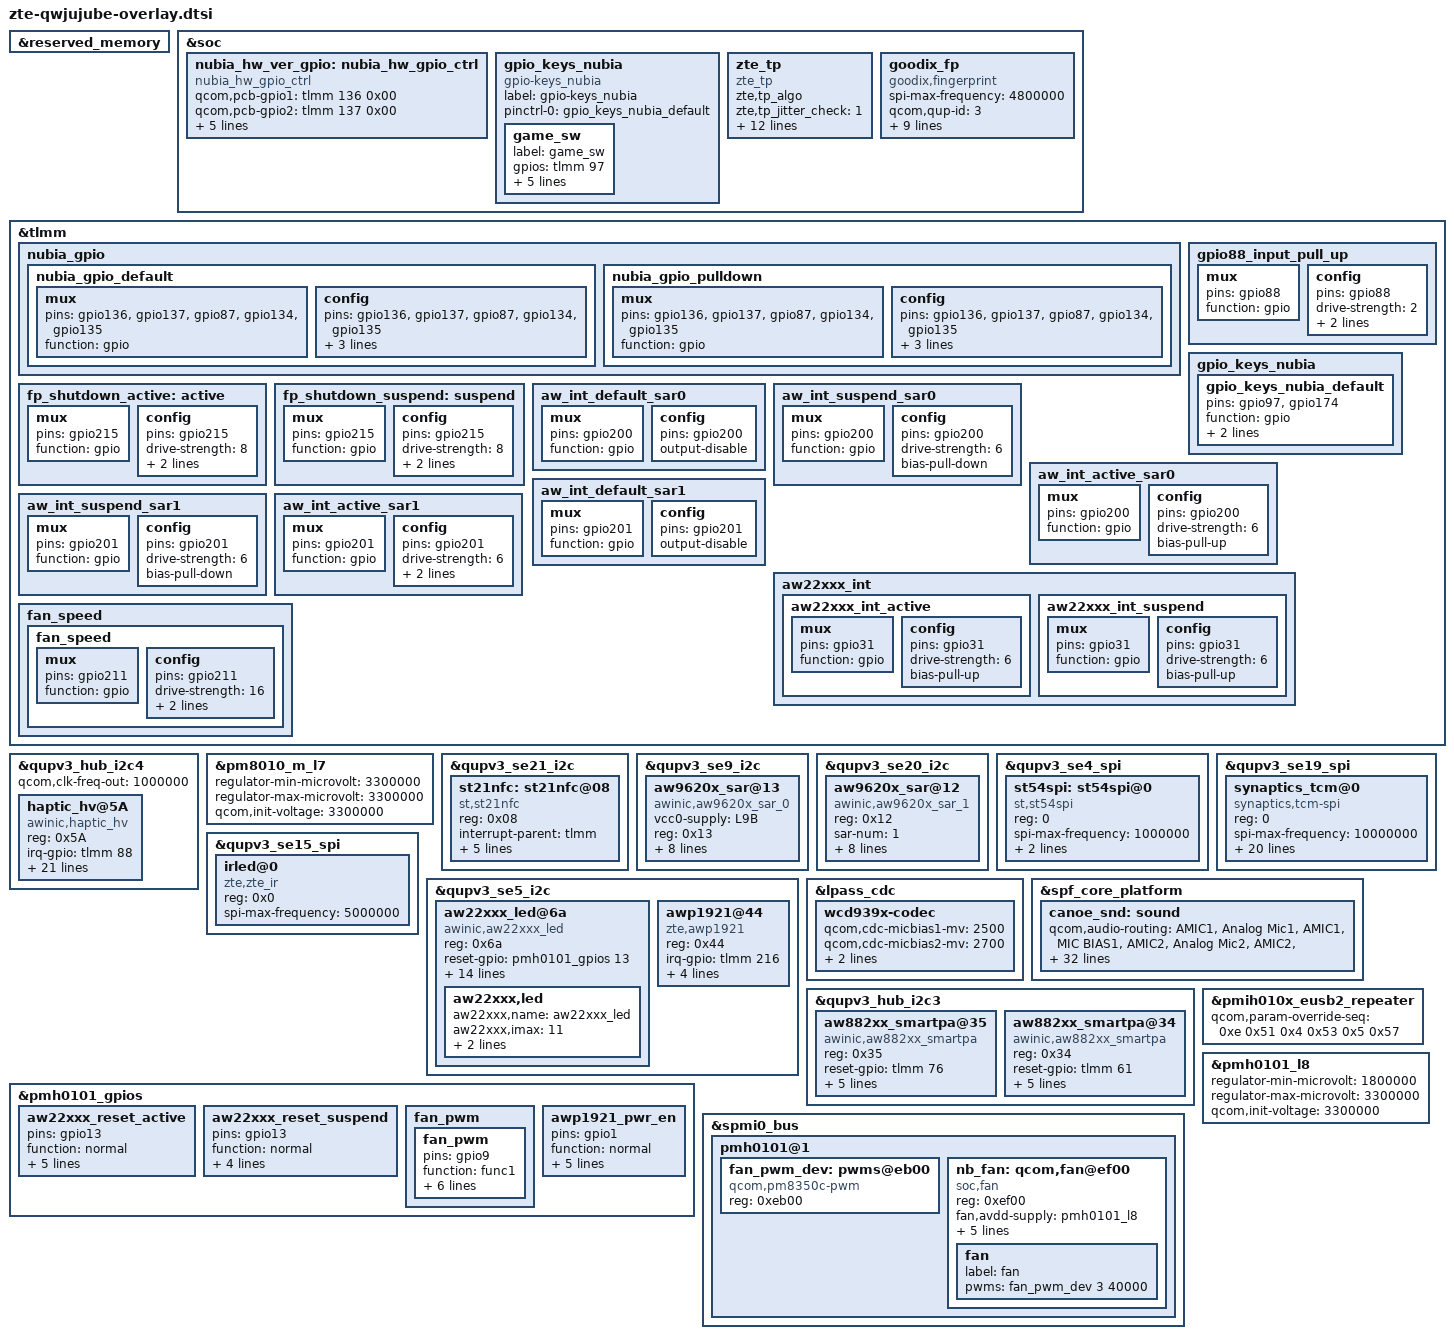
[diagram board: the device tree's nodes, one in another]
/* dtsi for aston board (NX809J)*/
#include <dt-bindings/gpio/gpio.h>

&reserved_memory {
};

&soc {
    nubia_hw_ver_gpio: nubia_hw_gpio_ctrl {
        compatible = "nubia_hw_gpio_ctrl";
        qcom,pcb-gpio1 = <&tlmm 136 0x00>;
        qcom,pcb-gpio2 = <&tlmm 137 0x00>;
        qcom,pcb-gpio3 = <&tlmm 87 0x00>;
        qcom,rf-gpio1 = <&tlmm 134 0x00>;
        qcom,rf-gpio2 = <&tlmm 135 0x00>;
        pinctrl-names = "pull_up_default","pull_down_default";
        pinctrl-0 = <&nubia_gpio_default>;
        pinctrl-1 = <&nubia_gpio_pulldown>;
    };

	gpio_keys_nubia {
		status = "ok";
		compatible = "gpio-keys_nubia";
		label = "gpio-keys_nubia";
		pinctrl-names ="default";
		pinctrl-0 = <&gpio_keys_nubia_default>;
		game_sw {
			label = "game_sw";
			/* In down state ↓, S=1/N=0, gpio97 is high, gpio174 is low; */
			/* In up state ↑, S=0/N=1, gpio97 is low, gpio174 is high; */
			gpios = <&tlmm 97 0>;
			gpion = <&tlmm 174 0>;
			linux,input-type = <5>;
			linux,code = <0x0f>;
			debounce-interval = <30>;
			gpio-key,wakeup;
		};
	};

	zte_tp:zte_tp {
		compatible = "zte_tp";
		zte,tp_algo;
		zte,tp_jitter_check = <1>;
		zte,tp_jitter_timer = <80>;
		zte,tp_long_press;
		zte,tp_long_press_timer = <800>;
		zte,tp_long_press_left_v = <20>;
		zte,tp_long_press_right_v = <20>;
		zte,tp_long_press_left_h = <20>; /*camera */
		zte,tp_long_press_right_h = <20>; /*charger */
		zte,tp_edge_click_suppression_pixel = <20>;
		zte,ufp_enable;
		zte,ufp_circle_center_x = <6080>;
		zte,ufp_circle_center_y = <20240>;
		zte,ufp_circle_radius = <1200>;
	};
};

&tlmm{
    nubia_gpio {
        nubia_gpio_default: nubia_gpio_default {
            mux {
                pins = "gpio136", "gpio137", "gpio87", "gpio134", "gpio135";
                function = "gpio";
            };
            config {
                pins = "gpio136", "gpio137", "gpio87", "gpio134", "gpio135";
                driver-strength = <2>; /* 2mA */
                bias-pull-up;
                input-enable;
            };
        };
        nubia_gpio_pulldown: nubia_gpio_pulldown {
            mux {
                pins = "gpio136", "gpio137", "gpio87", "gpio134", "gpio135";
                function = "gpio";
            };
            config {
                pins = "gpio136", "gpio137", "gpio87", "gpio134", "gpio135";
                driver-strength = <2>; /* 2mA */
                bias-pull-down;
                input-enable;
            };
        };
    };

    gpio88_input_pull_up: gpio88_input_pull_up {
            mux {
                pins = "gpio88";
                function = "gpio";
            };

            config {
                pins = "gpio88";
                drive-strength = <2>;
                bias-pull-up;
                input-enable;
            };
    };

	gpio_keys_nubia {
		gpio_keys_nubia_default: gpio_keys_nubia_default {
			pins = "gpio97", "gpio174";
			function = "gpio";
			input-enable;
			bias-disable;
		};
	};
};

/* add zte haptic  */
&qupv3_hub_i2c4  {
	status = "ok";
	qcom,clk-freq-out = <1000000>;
	haptic_hv@5A {
		compatible = "awinic,haptic_hv";
		reg = <0x5A>;
		irq-gpio = <&tlmm 88 0>;
		reset-gpio = <&tlmm 94 0>;
		pinctrl-names = "irq_active";
		pinctrl-0 = <&gpio88_input_pull_up>;
		f0_pre = < 1700 >;
		mode = /bits/ 8 < 5 >;

		aw8693x_f0_cali_percent = /bits/ 8 < 15 >;
		aw8693x_gain_bypass = /bits/ 8 < 1 >;
		aw8693x_uvlo_vol_default = /bits/ 8 < 0 >;
		aw8693x_cont_smart_loop = /bits/ 8 < 0 >;
		aw8693x_cont_drv1_lvl = /bits/ 8 < 0x7F >;
		aw8693x_cont_lra_vrms = < 1000 >;
		aw8693x_cont_drv1_time = /bits/ 8 < 0x04 >;
		aw8693x_cont_drv2_time = /bits/ 8 < 0x14 >;
		aw8693x_cont_track_margin = /bits/ 8 < 0x0F >;
		aw8693x_cont_brk_gain = /bits/ 8 < 0x08 >;
		aw8693x_cont_brk_time = /bits/ 8 < 0x08 >;
		aw8693x_duration_time = /bits/ 8 < 20 30 60 >;
		aw8693x_d2s_gain = /bits/ 8 < 0x04 >;
		aw8693x_trig_config = /bits/ 8 < 0 0 0 1 0 2 0 0
						 0 0 0 1 0 2 0 0
						 0 0 0 1 0 2 0 0 >;
		aw8693x_bst_vol_default = /bits/ 8 < 0x0f >;
		aw8693x_is_enabled_track_en;
		/* aw8693x_is_enabled_auto_bst; */
		/* aw8693x_is_enabled_one_wire; */
	};
};

&soc {
	goodix_fp {
		status = "ok";
		compatible = "goodix,fingerprint";
		spi-max-frequency = <4800000>;
		qcom,qup-id = <3>;
		reg = <0>;

		interrupt-parent = <&tlmm>;
		interrupts = <99 0x2008>;
		pinctrl-names = "goodix_active", "goodix_suspend";
		pinctrl-0 = <&fp_shutdown_active>;
		pinctrl-1 = <&fp_shutdown_suspend>;

		fp-gpio-reset = <&tlmm 215 0x0>;
		fp-gpio-irq = <&tlmm 99 0x2008>;
		vdd-supply = <&L7M>;
		interrupt-names = "goodix_wake_up";

		panel = <&dsi_bf375_rm692h5_6p8_magic_dsc_cmd>;
	};
};

&pm8010_m_l7 {
        regulator-min-microvolt = <3300000>;
        regulator-max-microvolt = <3300000>;
        qcom,init-voltage = <3300000>;
};

&tlmm {
    fp_shutdown_active:active{
        mux{
            pins = "gpio215";
            function = "gpio";
        };
        config{
            pins = "gpio215";
            drive-strength = <8>;
            bias-disable;
            output-high;
        };
    };

    fp_shutdown_suspend:suspend{
        mux{
            pins = "gpio215";
            function = "gpio";
        };
        config{
            pins = "gpio215";
            drive-strength = <8>;
            bias-disable;
            output-low;
        };
    };

	aw_int_default_sar0: aw_int_default_sar0 {
			mux {
				pins = "gpio200";
				function = "gpio";
			};
			config {
				pins = "gpio200";
				output-disable;
			};
		};
	aw_int_suspend_sar0: aw_int_suspend_sar0 {
		mux {
				pins = "gpio200";
				function = "gpio";
			};
		config {
				pins = "gpio200";
				drive-strength = <6>;
				bias-pull-down;
		   };
		};
	aw_int_active_sar0: aw_int_active_sar0 {
		mux {
				pins = "gpio200";
				function = "gpio";
			};
		config {
				pins = "gpio200";
				drive-strength = <6>;
				bias-pull-up;
			};
		};
	aw_int_default_sar1: aw_int_default_sar1 {
		mux {
				pins = "gpio201";
				function = "gpio";
		};
		config{
				pins = "gpio201";
				output-disable;
		};
	};
	aw_int_suspend_sar1: aw_int_suspend_sar1 {
		mux {
				pins = "gpio201";
				function = "gpio";
	};
		config{
				pins = "gpio201";
				drive-strength = <6>;
				bias-pull-down;
		};
	};
	aw_int_active_sar1: aw_int_active_sar1 {
		mux {
				pins = "gpio201";
				function = "gpio";
		};
		config {
				pins = "gpio201";
				drive-strength = <6>;
				bias-pull-up;
				qcom,i2c_pull = <0>;
		};
	};

};

&qupv3_se21_i2c {
    status = "ok";
    /delete-node/ nq@28;
    st21nfc: st21nfc@08 {
        compatible = "st,st21nfc";
        reg = <0x08>;
        interrupt-parent = <&tlmm>;
        interrupts = <75  0>;
        reset-gpios = <&tlmm 34 0x00>;
        irq-gpios = <&tlmm 75 0x00>;
        //boost-gpios = <&tlmm 90 0x00>;
        //pidle-gpios = <&tlmm 48 0x00>;
        clkreq-gpios = <&tlmm 35 0x00>;
        //clocks = <&clock_rpmh RPMH_RF_CLK3>;
        //clock-names = "nfc_ref_clk";
        st,clk_pinctrl;
        status = "ok";
    };
};

&qupv3_se9_i2c {
		status = "ok";
		aw9620x_sar@13 {
			compatible = "awinic,aw9620x_sar_0";
			vcc0-supply = <&L9B>;
			reg = <0x13>;
			sar-num = < 0 >;
			interrupt-parent = < &tlmm >;
			interrupts = <200 0>;
			irq-gpio = <&tlmm 200 0>;
			pinctrl-names = "aw_int_default_sar0", "aw_int_active_sar0", "aw_int_suspend_sar0";
			pinctrl-0 = <&aw_int_default_sar0>;
			pinctrl-1 = <&aw_int_active_sar0>;
			pinctrl-2 = <&aw_int_suspend_sar0>;
			channel_use_flag = <0x01>;
			status = "okay";
		};
};

&qupv3_se20_i2c {
		status = "ok";
		aw9620x_sar@12 {
			compatible = "awinic,aw9620x_sar_1";
			reg = < 0x12 >;
			sar-num = < 1 >;
			interrupt-parent = < &tlmm >;
			interrupts = <201 0>;
			irq-gpio = <&tlmm 201 0>;
			pinctrl-names = "aw_int_default_sar1", "aw_int_active_sar1", "aw_int_suspend_sar1";
			pinctrl-0 = <&aw_int_default_sar1>;
			pinctrl-1 = <&aw_int_active_sar1>;
			pinctrl-2 = <&aw_int_suspend_sar1>;
			vcc1-supply = <&L9B>;
			channel_use_flag = <0x01>;
			status = "okay";
		};
};

&qupv3_se4_spi {
    status = "ok";
    st54spi: st54spi@0 {
        compatible = "st,st54spi";
        reg = <0>;
        spi-max-frequency = <1000000>;
        /* gpio used as SE_PWR_REQ or SE_nRESET */
        gpio-power_nreset-std = <&tlmm 46 0x00>;

        /* Power management mode: none, ST54H (default), ST54J */
        power_mode = "ST54J";
        status = "ok";
    };
};

&qupv3_se19_spi {

	status = "ok";

	synaptics_tcm@0 {
		compatible = "synaptics,tcm-spi";
		reg = <0>;
		spi-max-frequency = <10000000>;
		interrupt-parent = <&tlmm>;
		interrupts = <158 0x2008>;
		synaptics,vdd-name = "vdd";
		synaptics,avdd-name = "avdd";
		vdd-supply = <&L4B>;
		avdd-supply = <&L14B>;
		synaptics,power-delay-ms = <200>;
		synaptics,irq-gpio = <&tlmm 158 0x2008>;
		synaptics,irq-on-state = <0>;
		synaptics,reset-gpio = <&tlmm 66 0x0000>;
		synaptics,reset-on-state = <0>;
		synaptics,reset-active-ms = <20>;
		synaptics,reset-delay-ms = <200>;
		synaptics,spi-mode = <0>;
		synaptics,spi-byte-delay-us = <0>;
		synaptics,spi-block-delay-us = <0>;

		pinctrl-names = "ts_active", "ts_suspend";
		pinctrl-0 = <&ts_active>;
		pinctrl-1 = <&ts_int_suspend &ts_reset_suspend>;
		pinctrl-2 = <&ts_release>;

		panel = <&dsi_bf375_rm692h5_6p8_magic_dsc_cmd>;
	};
};

&qupv3_se15_spi {
    status = "ok";
    irled@0 {
        status = "ok";
        compatible = "zte,zte_ir";
        reg = <0x0>;
        spi-max-frequency = <5000000>;
    };
};

&qupv3_se5_i2c {
        status = "okay";
	/*aw22xxx_led*/
	aw22xxx_led@6a {
	status = "okay";
		compatible = "awinic,aw22xxx_led";
		reg = <0x6a>;
		reset-gpio = <&pmh0101_gpios 13 0x0>;
		nubia_ver-gpio = <&tlmm 7 1>;
		interrupt-parent = <&tlmm>;
		interrupts = <31 0x2002>;
		irq-gpio = <&tlmm 31 0x2002>;
		qcom,clk-freq-out = <400000>;
		pinctrl-names = "aw22xxx_led_default", "aw22xxx_led_sleep";
		pinctrl-0 = <&aw22xxx_int_active &aw22xxx_reset_active>;
		pinctrl-1 = <&aw22xxx_int_suspend &aw22xxx_reset_suspend>;
		cfg_custom_en = <1>;
		/*aw22xxx_cfg_name[0:13] en flag */
		cfg_base_en = <1 1 1 1 0 0 0 0 1 1 1 1 1 1 1>;
		/*steady lighting up,breath,flashing,flow,ripple,echo,hopping,fast flashing,follows the audio,two flashing*/
		cfg_modex_count = <14 14 14 7 7 7 7 14 15 7>;
		touch_modex_count = <14 14 14 7 7 7 7 14 15 7>;
		fan_modex_count = <16 16 16 16 16>;
		aw22xxx,led {
			aw22xxx,name = "aw22xxx_led";
			aw22xxx,imax = <11>;
			aw22xxx,brightness = <128>;
			aw22xxx,max_brightness = <255>;
		};
	};

	awp1921@44 {
		compatible = "zte,awp1921","awinic,aw86320";
		reg = < 0x44 >;
		irq-gpio = <&tlmm 216 0x00>;
		power-en = <&pmh0101_gpios 1 0>;
		//is_fifo_method_play;
		is_reg_method_play;
		atsin0_polor = < 0x00 >;
		atsin0_phase = < 0x00 >;
		status = "okay";
	};
};

/*aw22xxx_led*/
&pmh0101_gpios {
    aw22xxx_reset_active: aw22xxx_reset_active {
        pins = "gpio13";
        function = "normal";
        qcom,drive-strength = <2>;
        input-disable;
        output-enable;
        output-high;
        power-source = <0>;
    };

    aw22xxx_reset_suspend: aw22xxx_reset_suspend {
        pins = "gpio13";
        function = "normal";
        qcom,drive-strength = <2>;
        input-disable;
        output-enable;
        output-low;
    };
};

&tlmm{
	aw22xxx_int {
		aw22xxx_int_active: aw22xxx_int_active {
			mux {
				pins = "gpio31";
				function = "gpio";
			};
			config {
				pins = "gpio31";
				drive-strength = <6>;
				bias-pull-up;
			};
		};
		aw22xxx_int_suspend: aw22xxx_int_suspend {
			mux {
				pins = "gpio31";
				function = "gpio";
			};
			config {
				pins = "gpio31";
				drive-strength = <6>;
				bias-pull-up;
			};
		};
	};
};

&lpass_cdc {
	wcd939x-codec {
		/* zte modify for redmagic headset no capture issue. */
		qcom,cdc-micbias1-mv = <2500>;
		qcom,cdc-micbias2-mv = <2700>;
		qcom,cdc-micbias3-mv = <2500>;
		qcom,cdc-micbias4-mv = <2500>;
	};
};

&spf_core_platform {
	canoe_snd: sound {
		qcom,audio-routing =
			"AMIC1", "Analog Mic1",
			"AMIC1", "MIC BIAS1",
			"AMIC2", "Analog Mic2",
			"AMIC2", "MIC BIAS2",
			"AMIC3", "Analog Mic3",
			"AMIC3", "MIC BIAS3",
			"AMIC4", "Analog Mic4",
			"AMIC4", "MIC BIAS4",
			"AMIC5", "Analog Mic5",
			"AMIC5", "MIC BIAS4",
			"VA AMIC1", "Analog Mic1",
			"VA AMIC1", "VA MIC BIAS1",
			"VA AMIC2", "Analog Mic2",
			"VA AMIC2", "VA MIC BIAS2",
			"VA AMIC3", "Analog Mic3",
			"VA AMIC3", "VA MIC BIAS3",
			"VA AMIC4", "Analog Mic4",
			"VA AMIC4", "VA MIC BIAS3",
			"VA AMIC5", "Analog Mic5",
			"VA AMIC5", "VA MIC BIAS4",
			"TX DMIC0", "Digital Mic0",
			"TX DMIC0", "MIC BIAS1",
			"TX DMIC1", "Digital Mic1",
			"TX DMIC1", "MIC BIAS1",
			"TX DMIC2", "Digital Mic2",
			"TX DMIC2", "MIC BIAS3",
			"TX DMIC3", "Digital Mic3",
			"TX DMIC3", "MIC BIAS3",
			"IN1_HPHL", "HPHL_OUT",
			"IN2_HPHR", "HPHR_OUT",
			"IN3_EAR", "AUX_OUT",
			"RX_TX DEC0_INP", "TX DEC0 MUX",
			"RX_TX DEC1_INP", "TX DEC1 MUX",
			"RX_TX DEC2_INP", "TX DEC2 MUX",
			"RX_TX DEC3_INP", "TX DEC3 MUX",
			"TX SWR_INPUT", "WCD_TX_OUTPUT",
			"VA SWR_INPUT", "VA_SWR_CLK",
			"VA SWR_INPUT", "WCD_TX_OUTPUT",
			"VA_AIF1 CAP", "VA_SWR_CLK",
			"VA_AIF2 CAP", "VA_SWR_CLK",
			"VA_AIF3 CAP", "VA_SWR_CLK",
			"VA DMIC0", "Digital Mic0",
			"VA DMIC1", "Digital Mic1",
			"VA DMIC2", "Digital Mic2",
			"VA DMIC3", "Digital Mic3",
			"VA DMIC0", "VA MIC BIAS1",
			"VA DMIC1", "VA MIC BIAS1",
			"VA DMIC2", "VA MIC BIAS3",
			"VA DMIC3", "VA MIC BIAS3";
		qcom,msm-mbhc-usbc-audio-supported = <0>;
		qcom,msm-mbhc-hphl-swh = <1>;
		qcom,msm-mbhc-gnd-swh = <1>;
		qcom,msm-mbhc-hs-mic-max-threshold-mv = <2700>;
	};
};

/* AWINIC AW882XX Smart PA */
&qupv3_hub_i2c3 {
	status = "okay";
	aw882xx_smartpa@35 {
		compatible = "awinic,aw882xx_smartpa";
		reg = <0x35>;
		reset-gpio = <&tlmm 76 0>;
		sync-load = <1>;
		sound-channel = <0>;
		aw-re-min = <4000>;
		aw-re-max= <30000>;
		aw-cali-mode = "none";
	};
	aw882xx_smartpa@34 {
		compatible = "awinic,aw882xx_smartpa";
		reg = <0x34>;
		reset-gpio = <&tlmm 61 0>;
		/* irq-gpio = <&tlmm xx 0x2008> */
		sync-load = <1>;
		sound-channel = <1>; /* 0: pri_l, 1:pri_r, 2:sec_l, 3:sec_r */
		aw-re-min = <4000>;
		aw-re-max= <30000>;
		aw-cali-mode = "none";
	};
};
/* AWINIC AW882XX Smart PA End */

/*fan start*/
&tlmm {
    fan_speed{
        fan_speed: fan_speed {
			mux {
				pins = "gpio211";
				function = "gpio";
			};
			config {
				pins = "gpio211";
				drive-strength = <16>;
				bias-pull-up;
				input-enable;
			};

        };
    };
};

&pmh0101_gpios {
    fan_pwm {
        fan_pwm: fan_pwm {
			pins = "gpio9";
			function = "func1";
			input-disable;
			output-enable;
			output-high;
			qcom,drive-strength = <3>;
			power-source = <0>;     /* 1.8V */
			drive-push-pull;
	    };
    };

    awp1921_pwr_en: awp1921_pwr_en {
        pins = "gpio1";
        function = "normal";
        qcom,drive-strength = <2>;
        input-disable;
        output-enable;
        output-high;
        power-source = <0>;      /* 1.8V */
    };

};

&pmih010x_eusb2_repeater {
	qcom,param-override-seq =
		/* <value reg_offset> */
		/* Adjust HS trasmit amplitude */
		<0xe 0x51
		/* HS Disconnect Threshold */
		 0x4 0x53
		/* Tx pre-emphasis tuning */
		 0x5 0x57>;
};

&pmh0101_l8 {
        regulator-min-microvolt = <1800000>;
        regulator-max-microvolt = <3300000>;
        qcom,init-voltage = <3300000>;
};


&spmi0_bus {
    pmh0101@1 {
        fan_pwm_dev: pwms@eb00 {
            compatible = "qcom,pm8350c-pwm";
            reg = <0xeb00>;
            #address-cells = <1>;
            #size-cells = <0>;
            #pwm-cells = <2>;
        };

        nb_fan: qcom,fan@ef00 {
            compatible = "soc,fan";
            reg = <0xef00>;
            fan,avdd-supply = <&pmh0101_l8>;
            regulator-names = "avdd";
            pinctrl-names ="default";
            pinctrl-0 =<&fan_speed &fan_pwm>;
            fan,pwm-gpio = <&pmh0101_gpios 9 GPIO_ACTIVE_HIGH>;
            fan,speed-gpio = <&tlmm 211 GPIO_ACTIVE_HIGH>;
            fan,voltage = <3300000>;
            fan {
                label = "fan";
                pwms = <&fan_pwm_dev 3 40000>;
            };
        };
    };
};
/*fan end*/
